# PY32F030xx register map
Vendor: Puya; Series: PY32F0; File version: 1.0.0
CPU: CM0+ r0p1, little endian, no MPU, no FPU, 4 interrupt priority bits
Registers are 32-bit, read-write, reset 0x0 unless marked. A register's access mark holds for its fields unless they carry their own. Offsets are from the block's base; [hi:lo] are bit positions.

## COMP2 — Comparator
Base 0x40010210
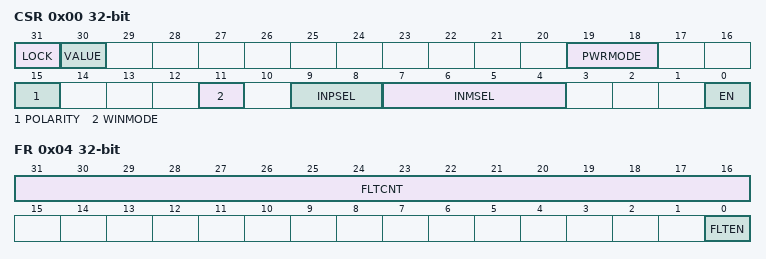
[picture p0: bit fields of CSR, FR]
0x00 CSR — COMP control and status register
  [31] LOCK — CSR register lock
    0=Unlocked (Comparator CSR bits are read-write); 1=Locked (Comparator CSR bits are read-only)
  [30] VALUE — Comparator output status
    on read: 0=Low (Comparator output is low); 1=High (Comparator output is high)
  [19:18] PWRMODE — Comparator power mode selector
    0=High speed / full power; 1=Medium speed / medium power; 2=Low speed / low power; 3=Very-low speed / ultra-low power
  [15] POLARITY — Comparator polarity selector
    0=NotInverted (Output is not inverted); 1=Inverted (Output is inverted)
  [11] WINMODE — Comparator non-inverting input selector for window mode
    0=Disabled (COMP2 non-inverting input is not connected to COMP1_INP); 1=Enabled (COMP2 non-inverting input is connected to COMP1_INP)
  [9:8] INPSEL — Comparator signal selector for non-inverting input
    0=PB4 (PB4 connected to non-inverting input); 1=PB6 (PB6 connected to non-inverting input); 2=PA3 (PA3 connected to non-inverting input); 3=PF3 (PF3 connected to non-inverting input)
  [7:4] INMSEL — Comparator signal selector for inverting input INM
    0=OneQuarterVRef (1/4 of VRefint); 1=ThreeQuarterVRef (3/4 of VRefint); 2=OneHalfVRef (1/2 of VRefint); 3=VRefint; 4=Vcc; 5=TS; 6=PB3 (PB3 connected to inverting input); 7=PB7 (PB6 connected to inverting input); 8=PA2 (PA2 connected to inverting input)
  [0] EN — COMP enable bit
    0=Disabled (Comparator 1 disabled); 1=Enabled (Comparator 1 enabled)
0x04 FR — Comparator Filter register
  [31:16] FLTCNT — Comparator filter and counter
  [0] FLTEN — Filter enable bit
    0=Disabled (Comparator digital filter disabled); 1=Enabled (Comparator digital filter enabled)

## PWR — Power control
Base 0x40007000
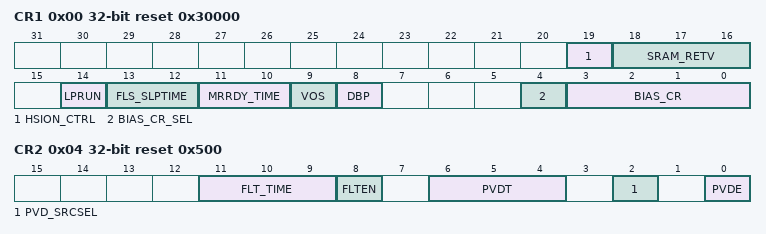
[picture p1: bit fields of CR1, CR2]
0x00 CR1 reset 0x30000 — Power control register 1
  [19] HSION_CTRL — HSI open time control
    0=WaiteMR (Enable HSI after MR is stable); 1=WakeOnVR (Enable HSI when VR is on (enable HSI immediately when wakeup))
  [18:16] SRAM_RETV — SRAM retention voltage control
    3=V0_9 (Supply voltage 0.9 V for SRAM); 4=V1_x (Supply voltage 1.0 or 1.2 V (depends on VOS) for SRAM)
  [14] LPRUN — Low-power run
    0=MainMode (Voltage regulator in Main mode in Low-power run mode); 1=LowPowerMode (Voltage regulator in low-power mode in Low-power run mode)
  [13:12] FLS_SLPTIME — Flash wait time after wakeup from the stop mode
    0=FiveMicroSec (Flash wait 5 us after wakeup from stop mode); 1=TwoMicroSec (Flash wait 2 us after wakeup from stop mode); 2=ThreeMicroSec (Flash wait 3 us after wakeup from stop mode); 3=ExcuteFromSRAM (Excute program from SRAM after wakeup from stop mode)
  [11:10] MRRDY_TIME — Time selection wakeup from LP to VR
    0=TwoMicroSec (MR ready after 2 us); 1=ThreeMicroSec (MR ready after 3 us); 2=FourMicroSec (MR ready after 4 us); 3=FiveMicroSec (MR ready after 5 us)
  [9] VOS — Voltage scaling range selection
    0=V1_2 (1.2 V (range 1)); 1=V1_0 (1.0 V (range 2))
  [8] DBP — Disable backup domain write protection
    0=Disabled (Access to RTC, RTC Backup and RCC CSR registers disabled); 1=Enabled (Access to RTC, RTC Backup and RCC CSR registers enabled)
  [4] BIAS_CR_SEL — MR Bias current selection
    0=FactoryConfig (Bias config from factory config bytes); 1=BiasCR (Bias config from BIAS_CR register)
  [3:0] BIAS_CR — MR Bias current
0x04 CR2 reset 0x500 — Power control register 2
  [11:9] FLT_TIME — Digital filter time configuration
    0=T30us (Filter time is about 30 us); 1=T60us (Filter time is about 60 us); 2=T120us (Filter time is about 120 us); 3=T480us (Filter time is about 480 us); 4=T1_92ms (Filter time is about 1.92 ms); 5=T3_8ms (Filter time is about 3.8 ms); 6=T30_7ms (Filter time is about 30.7 ms)
  [8] FLTEN — Digital filter enable
    0=Disabled (Digital filter disabled); 1=Enabled (Digital filter enabled)
  [6:4] PVDT — Power voltage detector threshold selection
    0=V1_8 (1.8 V); 1=V2_0 (2.0 V); 2=V2_2 (2.2 V); 3=V2_4 (2.4 V); 4=V2_6 (2.6 V); 5=V2_8 (2.8 V); 6=V3_0 (3.0 V); 7=V3_2 (3.2 V)
  [2] PVD_SRCSEL — Power voltage detector volatage selection
    0=Vcc (VCC as detector source); 1=PB7 (PB7 pin as detector source)
  [0] PVDE — Power voltage detector enable
    0=Disabled (PVD Disabled); 1=Enabled (PVD Enabled)
0x14 SR ro — Power status register
  [11] PVDO — PVD output
    0=AboveThreshold (VDD is higher than the PVD threshold selected with the PLS[2:0] bits); 1=BelowThreshold (VDD is lower than the PVD threshold selected with the PLS[2:0] bits)
